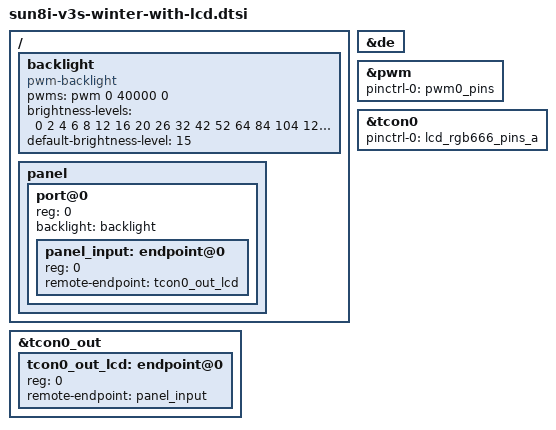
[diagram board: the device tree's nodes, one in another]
/*
 * Copyright (C) 2018 Icenowy Zheng <icenowy@aosc.io>
 *
 * SPDX-License-Identifier: (GPL-2.0+ OR X11)
 */

#include "sun8i-v3s-winter.dts"

 / {
	backlight: backlight {
		compatible = "pwm-backlight";
		pwms = <&pwm 0 40000 0>;
		brightness-levels = <0 2 4 6 8 12 16 20 26 32 42 52 64 84 104 128 160 200 255>;
		default-brightness-level = <15>;
	};

	panel: panel {
		#address-cells = <1>;
		#size-cells = <0>;

		port@0 {
			reg = <0>;
			backlight = <&backlight>;
			#address-cells = <1>;
			#size-cells = <0>;

			panel_input: endpoint@0 {
				reg = <0>;
				remote-endpoint = <&tcon0_out_lcd>;
			};
		};
	};
};

&de {
	status = "okay";
};

&pwm {
	pinctrl-names = "default";
	pinctrl-0 = <&pwm0_pins>;
	status = "okay";
};

&tcon0 {
	pinctrl-names = "default";
	pinctrl-0 = <&lcd_rgb666_pins_a>;
	status = "okay";
};

&tcon0_out {
	tcon0_out_lcd: endpoint@0 {
		reg = <0>;
		remote-endpoint = <&panel_input>;
	};
};
